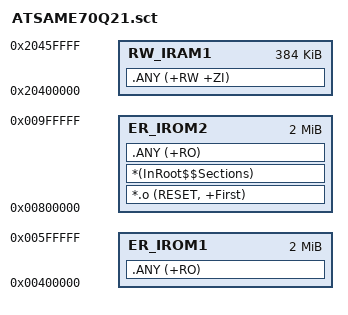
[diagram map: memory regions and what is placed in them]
; *************************************************************
; *** Scatter-Loading Description File generated by uVision ***
; *************************************************************

LR_IROM2 0x00800000 0x00200000  {    ; load region size_region
  ER_IROM2 0x00800000 0x00200000  {  ; load address = execution address
   *.o (RESET, +First)
   *(InRoot$$Sections)
   .ANY (+RO)
  }
  RW_IRAM1 0x20400000 0x00060000  {  ; RW data
   .ANY (+RW +ZI)
  }
}

LR_IROM1 0x00400000 0x00200000  {
  ER_IROM1 0x00400000 0x00200000  {  ; load address = execution address
   .ANY (+RO)
  }
}
